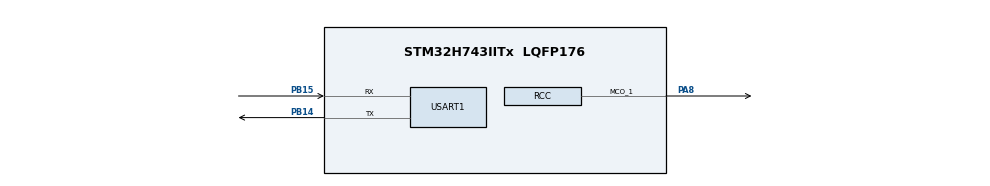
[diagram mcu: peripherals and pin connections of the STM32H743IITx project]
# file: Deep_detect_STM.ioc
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CORTEX_M7.CPU_DCache=Enabled
CORTEX_M7.CPU_ICache=Enabled
CORTEX_M7.default_mode_Activation=0
Mcu.Family=STM32H7
Mcu.Name=STM32H743IITx
Mcu.Package=LQFP176
NVIC.PriorityGroup=NVIC_PRIORITYGROUP_4
NVIC.USART1_IRQn=true\:0\:0\:false\:false\:true\:true\:true\:true
PA8.Mode=Clock-out-1
PA8.Signal=RCC_MCO_1
PB14.Mode=Asynchronous
PB14.Signal=USART1_TX
PB15.Mode=Asynchronous
PB15.Signal=USART1_RX
PC14-OSC32_IN\ (OSC32_IN).Mode=LSE-External-Oscillator
PC14-OSC32_IN\ (OSC32_IN).Signal=RCC_OSC32_IN
PC15-OSC32_OUT\ (OSC32_OUT).Mode=LSE-External-Oscillator
PC15-OSC32_OUT\ (OSC32_OUT).Signal=RCC_OSC32_OUT
PH0-OSC_IN\ (PH0).Mode=HSE-External-Oscillator
PH0-OSC_IN\ (PH0).Signal=RCC_OSC_IN
PH1-OSC_OUT\ (PH1).Mode=HSE-External-Oscillator
PH1-OSC_OUT\ (PH1).Signal=RCC_OSC_OUT
ProjectManager.HeapSize=0x200
ProjectManager.StackSize=0x400
ProjectManager.TargetToolchain=STM32CubeIDE
RCC.ADCFreq_Value=129000000
RCC.APB1Freq_Value=64000000
RCC.APB2Freq_Value=32000000
RCC.APB3Freq_Value=64000000
RCC.APB4Freq_Value=64000000
RCC.CortexFreq_Value=64000000
RCC.D2PPRE2=RCC_APB2_DIV2
RCC.HCLKFreq_Value=64000000
RCC.HSE_VALUE=8000000
RCC.PWR_Regulator_Voltage_Scale=PWR_REGULATOR_VOLTAGE_SCALE0
RCC.SYSCLKFreq_VALUE=64000000
RCC.USBFreq_Value=129000000
STMicroelectronics.X-CUBE-AI.8.1.0.ActivationBufferSizeList=7620
STMicroelectronics.X-CUBE-AI.8.1.0.ActivationBuffers=pool0
STMicroelectronics.X-CUBE-AI.8.1.0.ActivationNames=pool0
STMicroelectronics.X-CUBE-AI.8.1.0.ActivationSizes=AI_NETWORK_DATA_ACTIVATION_1_SIZE
STMicroelectronics.X-CUBE-AI.8.1.0.HeapSize=0x800
STMicroelectronics.X-CUBE-AI.8.1.0.InternalRamActivationBufferMaxSize=AI_NETWORK_DATA_ACTIVATIONS_SIZE
STMicroelectronics.X-CUBE-AI.8.1.0.LatestDirectoryUsed-69e165d922d82e774251df65bc6e205640fe162c35b353090582e5abe0d75ce8=D\:\\STM32CubeIDE_workspace\\STM32G070_AI_TEST-main
STMicroelectronics.X-CUBE-AI.8.1.0.MaximumNumberOfInputLayer=1
STMicroelectronics.X-CUBE-AI.8.1.0.MaximumNumberOfOutputLayer=1
STMicroelectronics.X-CUBE-AI.8.1.0.MaximumSizeOfInputLayer=1
STMicroelectronics.X-CUBE-AI.8.1.0.MaximumSizeOfOutputLayer=1
STMicroelectronics.X-CUBE-AI.8.1.0.ModelActualCompression-69e165d922d82e774251df65bc6e205640fe162c35b353090582e5abe0d75ce8=2.05
STMicroelectronics.X-CUBE-AI.8.1.0.ModelCompression-69e165d922d82e774251df65bc6e205640fe162c35b353090582e5abe0d75ce8=Medium
STMicroelectronics.X-CUBE-AI.8.1.0.ModelFlashOccupation-69e165d922d82e774251df65bc6e205640fe162c35b353090582e5abe0d75ce8=39610
STMicroelectronics.X-CUBE-AI.8.1.0.ModelHashList=69e165d922d82e774251df65bc6e205640fe162c35b353090582e5abe0d75ce8
STMicroelectronics.X-CUBE-AI.8.1.0.ModelKind-69e165d922d82e774251df65bc6e205640fe162c35b353090582e5abe0d75ce8=TFLITE
STMicroelectronics.X-CUBE-AI.8.1.0.ModelMacc-69e165d922d82e774251df65bc6e205640fe162c35b353090582e5abe0d75ce8=116080
STMicroelectronics.X-CUBE-AI.8.1.0.ModelName-69e165d922d82e774251df65bc6e205640fe162c35b353090582e5abe0d75ce8=network
STMicroelectronics.X-CUBE-AI.8.1.0.ModelNameList=network
STMicroelectronics.X-CUBE-AI.8.1.0.ModelRamOccupation-69e165d922d82e774251df65bc6e205640fe162c35b353090582e5abe0d75ce8=7620
STMicroelectronics.X-CUBE-AI.8.1.0.ModelStructureFile-69e165d922d82e774251df65bc6e205640fe162c35b353090582e5abe0d75ce8=D\:\\STM32CubeIDE_workspace\\STM32G070_AI_TEST-main\\trained_lstm.tflite
STMicroelectronics.X-CUBE-AI.8.1.0.ModelType-69e165d922d82e774251df65bc6e205640fe162c35b353090582e5abe0d75ce8=STM32Cube.AI runtime
STMicroelectronics.X-CUBE-AI.8.1.0.ReadyForCodeGeneration=true
STMicroelectronics.X-CUBE-AI.8.1.0.StackSize=0x800
STMicroelectronics.X-CUBE-AI.8.1.0.WorkingBufferStartAddrList=0xFFFFFFFF
STMicroelectronics.X-CUBE-AI.8.1.0.XAaCUBEAaAICcArtificialOoIntelligenceJjCore=true
STMicroelectronics.X-CUBE-AI.8.1.0.copyWeightToRam=false
STMicroelectronics.X-CUBE-AI.8.1.0.copyWeightToRam-69e165d922d82e774251df65bc6e205640fe162c35b353090582e5abe0d75ce8=false
STMicroelectronics.X-CUBE-AI.8.1.0.customLayerConfigEnabled=false
STMicroelectronics.X-CUBE-AI.8.1.0.customLayerConfigEnabled-69e165d922d82e774251df65bc6e205640fe162c35b353090582e5abe0d75ce8=false
STMicroelectronics.X-CUBE-AI.8.1.0.noOnnxIoTranspose=false
STMicroelectronics.X-CUBE-AI.8.1.0.noOnnxIoTranspose-69e165d922d82e774251df65bc6e205640fe162c35b353090582e5abe0d75ce8=false
STMicroelectronics.X-CUBE-AI.8.1.0.useInputAllocation=true
STMicroelectronics.X-CUBE-AI.8.1.0.useInputAllocation-69e165d922d82e774251df65bc6e205640fe162c35b353090582e5abe0d75ce8=true
STMicroelectronics.X-CUBE-AI.8.1.0.useOutputAllocation=true
STMicroelectronics.X-CUBE-AI.8.1.0.useOutputAllocation-69e165d922d82e774251df65bc6e205640fe162c35b353090582e5abe0d75ce8=true
USART1.VirtualMode-Asynchronous=VM_ASYNC
VP_CRC_VS_CRC.Mode=CRC_Activate
VP_STMicroelectronics.X-CUBE-AI_VS_ArtificialOoIntelligenceJjXAaCUBEAaAI_8.1.0.Mode=ArtificialOoIntelligenceJjXAaCUBEAaAI
board=custom

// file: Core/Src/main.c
/* USER CODE BEGIN Header */
/**
  ******************************************************************************
  * @file           : main.c
  * @brief          : Main program body
  ******************************************************************************
  * @attention
  *
  * Copyright (c) 2024 STMicroelectronics.
  * All rights reserved.
  *
  * This software is licensed under terms that can be found in the LICENSE file
  * in the root directory of this software component.
  * If no LICENSE file comes with this software, it is provided AS-IS.
  *
  ******************************************************************************
  */
/* USER CODE END Header */
#include "main.h"

/* USER CODE BEGIN Includes */
#include "stdio.h"
#include "ai_platform.h"
#include "network.h"
#include "network_data.h"
/* USER CODE END Includes */

CRC_HandleTypeDef hcrc;

UART_HandleTypeDef huart1;

void SystemClock_Config(void);
static void MX_GPIO_Init(void);
static void MX_CRC_Init(void);
static void MX_USART1_UART_Init(void);

/* USER CODE BEGIN 0 */
ai_handle network;
float aiInData[AI_NETWORK_IN_1_SIZE];
float aiOutData[AI_NETWORK_OUT_1_SIZE];
ai_u8 activations[AI_NETWORK_DATA_ACTIVATIONS_SIZE];

ai_buffer * ai_input;
ai_buffer * ai_output;

static void AI_Init(void);
static void AI_Run(float *pIn, float *pOut);
void PictureCharArrayToFloat(uint8_t *srcBuf,float *dstBuf,int len);

void Uart_send(char * str);
#define UART_BUFF_LEN 1024
#define ONE_FRAME_LEN 1+784+2
uint16_t uart_rx_length = 0;
uint8_t uart_rx_byte = 0;
uint8_t uart_rx_buffer[UART_BUFF_LEN];
volatile uint8_t goRunning = 0;

char message[]="hello";
/* USER CODE END 0 */

int main(void)
{
/* Enable the CPU Cache */

  /* Enable I-Cache---------------------------------------------------------*/
  SCB_EnableICache();

  /* Enable D-Cache---------------------------------------------------------*/
  SCB_EnableDCache();

  /* MCU Configuration--------------------------------------------------------*/

  /* Reset of all peripherals, Initializes the Flash interface and the Systick. */
  HAL_Init();

  /* Configure the system clock */
  SystemClock_Config();

  /* Initialize all configured peripherals */
  MX_GPIO_Init();
  MX_CRC_Init();
  MX_USART1_UART_Init();
  /* USER CODE BEGIN 2 */
  AI_Init();
  memset(uart_rx_buffer,0,784);
  HAL_UART_Receive_IT(&huart1, (uint8_t *)&uart_rx_byte, 1);
  /* USER CODE END 2 */

  /* Infinite loop */
  while (1)
  {

    /* USER CODE BEGIN 3 */
//	  Uart_send(message);
	  char str[10];
	  if(goRunning>0)
	  {
		  if(uart_rx_length == ONE_FRAME_LEN)
		  {
			  PictureCharArrayToFloat(uart_rx_buffer+1,aiInData,28*28);
			  AI_Run(aiInData, aiOutData);

		  }
		  memset(uart_rx_buffer,0,784);
		  goRunning = 0;
		  uart_rx_length = 0;
	  }
  }
  /* USER CODE END 3 */
}

void SystemClock_Config(void)
{
  RCC_OscInitTypeDef RCC_OscInitStruct = {0};
  RCC_ClkInitTypeDef RCC_ClkInitStruct = {0};

  /** Supply configuration update enable
  */
  HAL_PWREx_ConfigSupply(PWR_LDO_SUPPLY);

  /** Configure the main internal regulator output voltage
  */
  __HAL_PWR_VOLTAGESCALING_CONFIG(PWR_REGULATOR_VOLTAGE_SCALE1);

  while(!__HAL_PWR_GET_FLAG(PWR_FLAG_VOSRDY)) {}

  __HAL_RCC_SYSCFG_CLK_ENABLE();
  __HAL_PWR_VOLTAGESCALING_CONFIG(PWR_REGULATOR_VOLTAGE_SCALE0);

  while(!__HAL_PWR_GET_FLAG(PWR_FLAG_VOSRDY)) {}

  /** Initializes the RCC Oscillators according to the specified parameters
  * in the RCC_OscInitTypeDef structure.
  */
  RCC_OscInitStruct.OscillatorType = RCC_OSCILLATORTYPE_HSI;
  RCC_OscInitStruct.HSIState = RCC_HSI_DIV1;
  RCC_OscInitStruct.HSICalibrationValue = RCC_HSICALIBRATION_DEFAULT;
  RCC_OscInitStruct.PLL.PLLState = RCC_PLL_NONE;
  if (HAL_RCC_OscConfig(&RCC_OscInitStruct) != HAL_OK)
  {
    Error_Handler();
  }

  /** Initializes the CPU, AHB and APB buses clocks
  */
  RCC_ClkInitStruct.ClockType = RCC_CLOCKTYPE_HCLK|RCC_CLOCKTYPE_SYSCLK
                              |RCC_CLOCKTYPE_PCLK1|RCC_CLOCKTYPE_PCLK2
                              |RCC_CLOCKTYPE_D3PCLK1|RCC_CLOCKTYPE_D1PCLK1;
  RCC_ClkInitStruct.SYSCLKSource = RCC_SYSCLKSOURCE_HSI;
  RCC_ClkInitStruct.SYSCLKDivider = RCC_SYSCLK_DIV1;
  RCC_ClkInitStruct.AHBCLKDivider = RCC_HCLK_DIV1;
  RCC_ClkInitStruct.APB3CLKDivider = RCC_APB3_DIV1;
  RCC_ClkInitStruct.APB1CLKDivider = RCC_APB1_DIV1;
  RCC_ClkInitStruct.APB2CLKDivider = RCC_APB2_DIV2;
  RCC_ClkInitStruct.APB4CLKDivider = RCC_APB4_DIV1;

  if (HAL_RCC_ClockConfig(&RCC_ClkInitStruct, FLASH_LATENCY_0) != HAL_OK)
  {
    Error_Handler();
  }
  HAL_RCC_MCOConfig(RCC_MCO1, RCC_MCO1SOURCE_HSI, RCC_MCODIV_1);
}

static void MX_CRC_Init(void)
{

  hcrc.Instance = CRC;
  hcrc.Init.DefaultPolynomialUse = DEFAULT_POLYNOMIAL_ENABLE;
  hcrc.Init.DefaultInitValueUse = DEFAULT_INIT_VALUE_ENABLE;
  hcrc.Init.InputDataInversionMode = CRC_INPUTDATA_INVERSION_NONE;
  hcrc.Init.OutputDataInversionMode = CRC_OUTPUTDATA_INVERSION_DISABLE;
  hcrc.InputDataFormat = CRC_INPUTDATA_FORMAT_BYTES;
  if (HAL_CRC_Init(&hcrc) != HAL_OK)
  {
    Error_Handler();
  }

}

static void MX_USART1_UART_Init(void)
{

  huart1.Instance = USART1;
  huart1.Init.BaudRate = 115200;
  huart1.Init.WordLength = UART_WORDLENGTH_8B;
  huart1.Init.StopBits = UART_STOPBITS_1;
  huart1.Init.Parity = UART_PARITY_NONE;
  huart1.Init.Mode = UART_MODE_TX_RX;
  huart1.Init.HwFlowCtl = UART_HWCONTROL_NONE;
  huart1.Init.OverSampling = UART_OVERSAMPLING_16;
  huart1.Init.OneBitSampling = UART_ONE_BIT_SAMPLE_DISABLE;
  huart1.Init.ClockPrescaler = UART_PRESCALER_DIV1;
  huart1.AdvancedInit.AdvFeatureInit = UART_ADVFEATURE_NO_INIT;
  if (HAL_UART_Init(&huart1) != HAL_OK)
  {
    Error_Handler();
  }
  if (HAL_UARTEx_SetTxFifoThreshold(&huart1, UART_TXFIFO_THRESHOLD_1_8) != HAL_OK)
  {
    Error_Handler();
  }
  if (HAL_UARTEx_SetRxFifoThreshold(&huart1, UART_RXFIFO_THRESHOLD_1_8) != HAL_OK)
  {
    Error_Handler();
  }
  if (HAL_UARTEx_DisableFifoMode(&huart1) != HAL_OK)
  {
    Error_Handler();
  }

}

static void MX_GPIO_Init(void)
{
  GPIO_InitTypeDef GPIO_InitStruct = {0};

  /* GPIO Ports Clock Enable */
  __HAL_RCC_GPIOC_CLK_ENABLE();
  __HAL_RCC_GPIOH_CLK_ENABLE();
  __HAL_RCC_GPIOB_CLK_ENABLE();
  __HAL_RCC_GPIOA_CLK_ENABLE();

  /*Configure GPIO pin : PA8 */
  GPIO_InitStruct.Pin = GPIO_PIN_8;
  GPIO_InitStruct.Mode = GPIO_MODE_AF_PP;
  GPIO_InitStruct.Pull = GPIO_NOPULL;
  GPIO_InitStruct.Speed = GPIO_SPEED_FREQ_LOW;
  GPIO_InitStruct.Alternate = GPIO_AF0_MCO;
  HAL_GPIO_Init(GPIOA, &GPIO_InitStruct);

}

/* USER CODE BEGIN 4 */
void HAL_UART_RxCpltCallback(UART_HandleTypeDef *UartHandle)
{
	if(goRunning ==0)
	{
		if (uart_rx_length < UART_BUFF_LEN)
		{
			uart_rx_buffer[uart_rx_length] = uart_rx_byte;
			uart_rx_length++;

			if (uart_rx_byte == '\n')
			{
				goRunning = 1;
			}
		}
		else
		{
			//rt_kprintf("rx len over");
			uart_rx_length = 0;
		}
	}
	HAL_UART_Receive_IT(&huart1, (uint8_t *)&uart_rx_byte, 1);
}

void Uart_send(char * str)
{
	HAL_UART_Transmit(&huart1, (uint8_t *)str, strlen(str),0xffff);
}

static void AI_Init(void)
{
  ai_error err;

  /* Create a local array with the addresses of the activations buffers */
  const ai_handle act_addr[] = { activations };
  /* Create an instance of the model */
  err = ai_network_create_and_init(&network, act_addr, NULL);
  if (err.type != AI_ERROR_NONE) {
    printf("ai_network_create error - type=%d code=%d\r\n", err.type, err.code);
    Error_Handler();
  }
  ai_input = ai_network_inputs_get(network, NULL);
  ai_output = ai_network_outputs_get(network, NULL);
}

static void AI_Run(float *pIn, float *pOut)
{
	char logStr[100];
	char detect[50];
	int count = 0;
	float max = 0;
  ai_i32 batch;
  ai_error err;

  /* Update IO handlers with the data payload */
  ai_input[0].data = AI_HANDLE_PTR(pIn);
  ai_output[0].data = AI_HANDLE_PTR(pOut);

  batch = ai_network_run(network, ai_input, ai_output);
  if (batch != 1) {
    err = ai_network_get_error(network);
    printf("AI ai_network_run error - type=%d code=%d\r\n", err.type, err.code);
    Error_Handler();
  }
  for (uint32_t i = 0; i < AI_NETWORK_OUT_1_SIZE; i++) {

	  Uart_send("number:");
	  sprintf(logStr,"%d  %8.6f\r\n",i,aiOutData[i]);
	  Uart_send(logStr);
	  if(max<aiOutData[i])
	  {
		  count = i;
		  max= aiOutData[i];
	  }
  }
  sprintf(logStr,"current number is %d\r\n",count);
  Uart_send(logStr);
}

void PictureCharArrayToFloat(uint8_t *srcBuf,float *dstBuf,int len)
{
	for(int i=0;i<len;i++)
	{
		dstBuf[i] = srcBuf[i];//==1?0:1;
	}
}
/* USER CODE END 4 */

void Error_Handler(void)
{
  __disable_irq();
  while (1)
  {
  }
}
